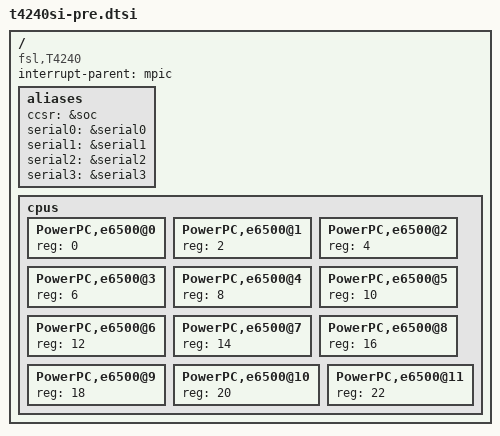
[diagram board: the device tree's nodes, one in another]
/*
 * T4240 Silicon/SoC Device Tree Source (pre include)
 *
 * Copyright 2012 Freescale Semiconductor Inc.
 *
 * Redistribution and use in source and binary forms, with or without
 * modification, are permitted provided that the following conditions are met:
 *     * Redistributions of source code must retain the above copyright
 *       notice, this list of conditions and the following disclaimer.
 *     * Redistributions in binary form must reproduce the above copyright
 *       notice, this list of conditions and the following disclaimer in the
 *       documentation and/or other materials provided with the distribution.
 *     * Neither the name of Freescale Semiconductor nor the
 *       names of its contributors may be used to endorse or promote products
 *       derived from this software without specific prior written permission.
 *
 *
 * ALTERNATIVELY, this software may be distributed under the terms of the
 * GNU General Public License ("GPL") as published by the Free Software
 * Foundation, either version 2 of that License or (at your option) any
 * later version.
 *
 * THIS SOFTWARE IS PROVIDED BY Freescale Semiconductor ``AS IS'' AND ANY
 * EXPRESS OR IMPLIED WARRANTIES, INCLUDING, BUT NOT LIMITED TO, THE IMPLIED
 * WARRANTIES OF MERCHANTABILITY AND FITNESS FOR A PARTICULAR PURPOSE ARE
 * DISCLAIMED. IN NO EVENT SHALL Freescale Semiconductor BE LIABLE FOR ANY
 * DIRECT, INDIRECT, INCIDENTAL, SPECIAL, EXEMPLARY, OR CONSEQUENTIAL DAMAGES
 * (INCLUDING, BUT NOT LIMITED TO, PROCUREMENT OF SUBSTITUTE GOODS OR SERVICES;
 * LOSS OF USE, DATA, OR PROFITS; OR BUSINESS INTERRUPTION) HOWEVER CAUSED AND
 * ON ANY THEORY OF LIABILITY, WHETHER IN CONTRACT, STRICT LIABILITY, OR TORT
 * (INCLUDING NEGLIGENCE OR OTHERWISE) ARISING IN ANY WAY OUT OF THE USE OF THIS
 * SOFTWARE, EVEN IF ADVISED OF THE POSSIBILITY OF SUCH DAMAGE.
 */

/dts-v1/;
/ {
	compatible = "fsl,T4240";
	#address-cells = <2>;
	#size-cells = <2>;
	interrupt-parent = <&mpic>;

	aliases {
		ccsr = &soc;

		serial0 = &serial0;
		serial1 = &serial1;
		serial2 = &serial2;
		serial3 = &serial3;
	};

	cpus {
		#address-cells = <1>;
		#size-cells = <0>;

		PowerPC,e6500@0 {
			device_type = "cpu";
			reg = <0>;
		};
		PowerPC,e6500@1 {
			device_type = "cpu";
			reg = <2>;
		};
		PowerPC,e6500@2 {
			device_type = "cpu";
			reg = <4>;
		};
		PowerPC,e6500@3 {
			device_type = "cpu";
			reg = <6>;
		};

		PowerPC,e6500@4 {
			device_type = "cpu";
			reg = <8>;
		};
		PowerPC,e6500@5 {
			device_type = "cpu";
			reg = <10>;
		};
		PowerPC,e6500@6 {
			device_type = "cpu";
			reg = <12>;
		};
		PowerPC,e6500@7 {
			device_type = "cpu";
			reg = <14>;
		};

		PowerPC,e6500@8 {
			device_type = "cpu";
			reg = <16>;
		};
		PowerPC,e6500@9 {
			device_type = "cpu";
			reg = <18>;
		};
		PowerPC,e6500@10 {
			device_type = "cpu";
			reg = <20>;
		};
		PowerPC,e6500@11 {
			device_type = "cpu";
			reg = <22>;
		};
	};
};
